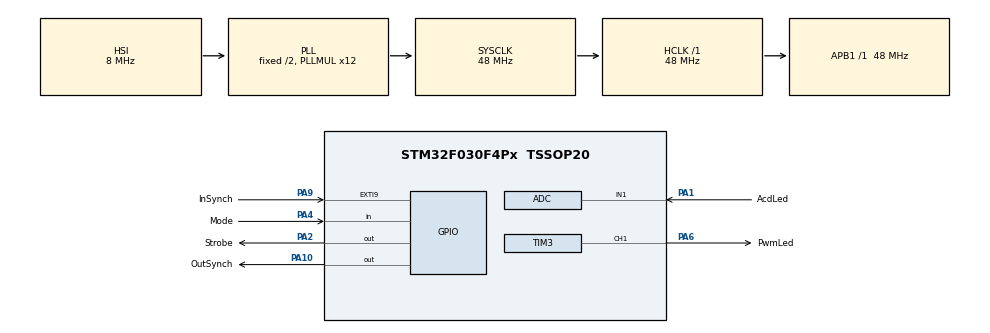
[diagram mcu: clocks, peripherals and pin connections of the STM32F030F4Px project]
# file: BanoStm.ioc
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ADC.ClockPrescaler=ADC_CLOCK_ASYNC_DIV1
ADC.ContinuousConvMode=DISABLE
ADC.DMAContinuousRequests=DISABLE
ADC.DataAlign=ADC_DATAALIGN_RIGHT
ADC.DiscontinuousConvMode=DISABLE
ADC.EOCSelection=ADC_EOC_SINGLE_CONV
ADC.EnableAnalogWatchDog=false
ADC.ExternalTrigConv=ADC_SOFTWARE_START
ADC.ExternalTrigConvEdge=ADC_EXTERNALTRIGCONVEDGE_NONE
ADC.LowPowerAutoPowerOff=DISABLE
ADC.LowPowerAutoWait=DISABLE
ADC.Overrun=ADC_OVR_DATA_PRESERVED
ADC.Resolution=ADC_RESOLUTION_12B
ADC.SamplingTime=ADC_SAMPLETIME_1CYCLE_5
ADC.ScanConvMode=ADC_SCAN_DIRECTION_FORWARD
Mcu.Family=STM32F0
Mcu.Name=STM32F030F4Px
Mcu.Package=TSSOP20
NVIC.ADC1_IRQn=true\:0\:0\:false\:true\:true\:3\:true
NVIC.EXTI4_15_IRQn=true\:0\:0\:false\:true\:true\:4\:true
NVIC.RCC_IRQn=true\:0\:0\:false\:false\:false\:true
NVIC.TIM16_IRQn=true\:0\:0\:false\:false\:true\:true
NVIC.TIM1_BRK_UP_TRG_COM_IRQn=true\:0\:0\:false\:true\:true\:2\:true
NVIC.TIM1_CC_IRQn=true\:0\:0\:false\:true\:true\:1\:true
PA1.GPIO_Label=AcdLed
PA1.GPIO_Mode=GPIO_MODE_ANALOG
PA1.GPIO_PuPd=GPIO_NOPULL
PA1.Signal=SharedAnalog_PA1
PA10.GPIO_Label=OutSynch
PA10.Signal=GPIO_Output
PA13.Mode=Serial_Wire
PA13.Signal=SYS_SWDIO
PA14.Mode=Serial_Wire
PA14.Signal=SYS_SWCLK
PA2.GPIO_Label=Strobe
PA2.GPIO_ModeDefaultOutputPP=GPIO_MODE_OUTPUT_PP
PA2.GPIO_PuPd=GPIO_NOPULL
PA2.GPIO_Speed=GPIO_SPEED_FREQ_LOW
PA2.PinState=GPIO_PIN_RESET
PA2.Signal=GPIO_Output
PA4.GPIO_Label=Mode
PA4.GPIO_Mode=GPIO_MODE_INPUT
PA4.GPIO_PuPd=GPIO_NOPULL
PA4.Signal=GPIO_Input
PA6.GPIO_Label=PwmLed
PA6.GPIO_ModeDefaultPP=GPIO_MODE_AF_PP
PA6.GPIO_PuPd=GPIO_NOPULL
PA6.GPIO_Speed=GPIO_SPEED_FREQ_LOW
PA6.Signal=S_TIM3_CH1
PA9.GPIO_Label=InSynch
PA9.GPIO_ModeDefaultEXTI=GPIO_MODE_IT_FALLING
PA9.Signal=GPXTI9
PF0-OSC_IN.Mode=HSE-External-Oscillator
PF0-OSC_IN.Signal=RCC_OSC_IN
PF1-OSC_OUT.Mode=HSE-External-Oscillator
PF1-OSC_OUT.Signal=RCC_OSC_OUT
ProjectManager.HeapSize=0x200
ProjectManager.StackSize=0x400
ProjectManager.TargetToolchain=MDK-ARM V5
RCC.AHBFreq_Value=48000000
RCC.APB1Freq_Value=48000000
RCC.APB1TimFreq_Value=48000000
RCC.HCLKFreq_Value=48000000
RCC.PLLMUL=RCC_PLL_MUL12
RCC.SYSCLKFreq_VALUE=48000000
RCC.SYSCLKSource=RCC_SYSCLKSOURCE_PLLCLK
SH.S_TIM3_CH1.0=TIM3_CH1,PWM Generation1 CH1
SH.SharedAnalog_PA1.0=GPIO_Analog
SH.SharedAnalog_PA1.1=ADC_IN1,IN1
TIM1.AutoReloadPreload=TIM_AUTORELOAD_PRELOAD_ENABLE
TIM1.Channel-Output\ Compare1\ No\ Output=TIM_CHANNEL_1
TIM1.Channel-Output\ Compare2\ No\ Output=TIM_CHANNEL_2
TIM1.Period=1500
TIM1.Prescaler=47999
TIM16.AutoReloadPreload=TIM_AUTORELOAD_PRELOAD_ENABLE
TIM16.Period=48
TIM16.Prescaler=999
TIM3.AutoReloadPreload=TIM_AUTORELOAD_PRELOAD_ENABLE
TIM3.Channel-PWM\ Generation1\ CH1=TIM_CHANNEL_1
TIM3.Period=100
TIM3.Prescaler=47
VP_TIM16_VS_ClockSourceINT.Mode=Enable_Timer
VP_TIM1_VS_no_output1.Mode=Output Compare1 No Output
VP_TIM1_VS_no_output2.Mode=Output Compare2 No Output
board=custom

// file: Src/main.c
/**
  ******************************************************************************
  * @file           : main.c
  * @brief          : Main program body
  ******************************************************************************
  ** This notice applies to any and all portions of this file
  * that are not between comment pairs USER CODE BEGIN and
  * USER CODE END. Other portions of this file, whether
  * inserted by the user or by software development tools
  * are owned by their respective copyright owners.
  *
  * COPYRIGHT(c) 2022 STMicroelectronics
  *
  * Redistribution and use in source and binary forms, with or without modification,
  * are permitted provided that the following conditions are met:
  *   1. Redistributions of source code must retain the above copyright notice,
  *      this list of conditions and the following disclaimer.
  *   2. Redistributions in binary form must reproduce the above copyright notice,
  *      this list of conditions and the following disclaimer in the documentation
  *      and/or other materials provided with the distribution.
  *   3. Neither the name of STMicroelectronics nor the names of its contributors
  *      may be used to endorse or promote products derived from this software
  *      without specific prior written permission.
  *
  * THIS SOFTWARE IS PROVIDED BY THE COPYRIGHT HOLDERS AND CONTRIBUTORS "AS IS"
  * AND ANY EXPRESS OR IMPLIED WARRANTIES, INCLUDING, BUT NOT LIMITED TO, THE
  * IMPLIED WARRANTIES OF MERCHANTABILITY AND FITNESS FOR A PARTICULAR PURPOSE ARE
  * DISCLAIMED. IN NO EVENT SHALL THE COPYRIGHT HOLDER OR CONTRIBUTORS BE LIABLE
  * FOR ANY DIRECT, INDIRECT, INCIDENTAL, SPECIAL, EXEMPLARY, OR CONSEQUENTIAL
  * DAMAGES (INCLUDING, BUT NOT LIMITED TO, PROCUREMENT OF SUBSTITUTE GOODS OR
  * SERVICES; LOSS OF USE, DATA, OR PROFITS; OR BUSINESS INTERRUPTION) HOWEVER
  * CAUSED AND ON ANY THEORY OF LIABILITY, WHETHER IN CONTRACT, STRICT LIABILITY,
  * OR TORT (INCLUDING NEGLIGENCE OR OTHERWISE) ARISING IN ANY WAY OUT OF THE USE
  * OF THIS SOFTWARE, EVEN IF ADVISED OF THE POSSIBILITY OF SUCH DAMAGE.
  *
  ******************************************************************************
  */
#include "main.h"
#include "stm32f0xx_hal.h"
#include "adc.h"
#include "tim.h"
#include "gpio.h"

/* USER CODE BEGIN PV */
/* Private variables ---------------------------------------------------------*/

/* USER CODE END PV */

void SystemClock_Config(void);
static void MX_NVIC_Init(void);

/* USER CODE BEGIN PFP */
/* Private function prototypes -----------------------------------------------*/

/* USER CODE END PFP */

/* USER CODE BEGIN 0 */
uint8_t start_timer = 0;
/* USER CODE END 0 */

int main(void)
{

  /* MCU Configuration----------------------------------------------------------*/

  /* Reset of all peripherals, Initializes the Flash interface and the Systick. */
  HAL_Init();

  /* Configure the system clock */
  SystemClock_Config();

  /* Initialize all configured peripherals */
  MX_GPIO_Init();
  MX_TIM3_Init();
  MX_ADC_Init();
  MX_TIM1_Init();
  MX_TIM16_Init();

  /* Initialize interrupts */
  MX_NVIC_Init();
  /* USER CODE BEGIN 2 */

	//HAL_TIM_Base_Start(&htim1);
	HAL_TIM_Base_Start_IT(&htim1);

	//__HAL_TIM_ENABLE_IT(&htim1, TIM_IT_CC1);
	__HAL_TIM_ENABLE_IT(&htim1, TIM_IT_UPDATE);

  /* USER CODE END 2 */

  /* Infinite loop */
  /* USER CODE BEGIN WHILE */
  while (1)
  {
		if(start_timer)
		{
			__HAL_TIM_SET_COUNTER(&htim1, 0);
			start_timer = 0;
		}
  /* USER CODE END WHILE */

  }

}

void SystemClock_Config(void)
{

  RCC_OscInitTypeDef RCC_OscInitStruct;
  RCC_ClkInitTypeDef RCC_ClkInitStruct;

    /**Initializes the CPU, AHB and APB busses clocks
    */
  RCC_OscInitStruct.OscillatorType = RCC_OSCILLATORTYPE_HSI|RCC_OSCILLATORTYPE_HSI14;
  RCC_OscInitStruct.HSIState = RCC_HSI_ON;
  RCC_OscInitStruct.HSI14State = RCC_HSI14_ON;
  RCC_OscInitStruct.HSICalibrationValue = 16;
  RCC_OscInitStruct.HSI14CalibrationValue = 16;
  RCC_OscInitStruct.PLL.PLLState = RCC_PLL_ON;
  RCC_OscInitStruct.PLL.PLLSource = RCC_PLLSOURCE_HSI;
  RCC_OscInitStruct.PLL.PLLMUL = RCC_PLL_MUL12;
  RCC_OscInitStruct.PLL.PREDIV = RCC_PREDIV_DIV1;
  if (HAL_RCC_OscConfig(&RCC_OscInitStruct) != HAL_OK)
  {
    _Error_Handler(__FILE__, __LINE__);
  }

    /**Initializes the CPU, AHB and APB busses clocks
    */
  RCC_ClkInitStruct.ClockType = RCC_CLOCKTYPE_HCLK|RCC_CLOCKTYPE_SYSCLK
                              |RCC_CLOCKTYPE_PCLK1;
  RCC_ClkInitStruct.SYSCLKSource = RCC_SYSCLKSOURCE_PLLCLK;
  RCC_ClkInitStruct.AHBCLKDivider = RCC_SYSCLK_DIV1;
  RCC_ClkInitStruct.APB1CLKDivider = RCC_HCLK_DIV1;

  if (HAL_RCC_ClockConfig(&RCC_ClkInitStruct, FLASH_LATENCY_1) != HAL_OK)
  {
    _Error_Handler(__FILE__, __LINE__);
  }

    /**Configure the Systick interrupt time
    */
  HAL_SYSTICK_Config(HAL_RCC_GetHCLKFreq()/1000);

    /**Configure the Systick
    */
  HAL_SYSTICK_CLKSourceConfig(SYSTICK_CLKSOURCE_HCLK);

  /* SysTick_IRQn interrupt configuration */
  HAL_NVIC_SetPriority(SysTick_IRQn, 0, 0);
}

/**
  * @brief NVIC Configuration.
  * @retval None
  */
static void MX_NVIC_Init(void)
{
  /* TIM1_CC_IRQn interrupt configuration */
  HAL_NVIC_SetPriority(TIM1_CC_IRQn, 0, 0);
  HAL_NVIC_EnableIRQ(TIM1_CC_IRQn);
  /* TIM1_BRK_UP_TRG_COM_IRQn interrupt configuration */
  HAL_NVIC_SetPriority(TIM1_BRK_UP_TRG_COM_IRQn, 0, 0);
  HAL_NVIC_EnableIRQ(TIM1_BRK_UP_TRG_COM_IRQn);
  /* ADC1_IRQn interrupt configuration */
  HAL_NVIC_SetPriority(ADC1_IRQn, 0, 0);
  HAL_NVIC_EnableIRQ(ADC1_IRQn);
  /* EXTI4_15_IRQn interrupt configuration */
  HAL_NVIC_SetPriority(EXTI4_15_IRQn, 0, 0);
  HAL_NVIC_EnableIRQ(EXTI4_15_IRQn);
}

void _Error_Handler(char *file, int line)
{
  while(1)
  {
  }
}

/************************ (C) COPYRIGHT STMicroelectronics *****END OF FILE****/
